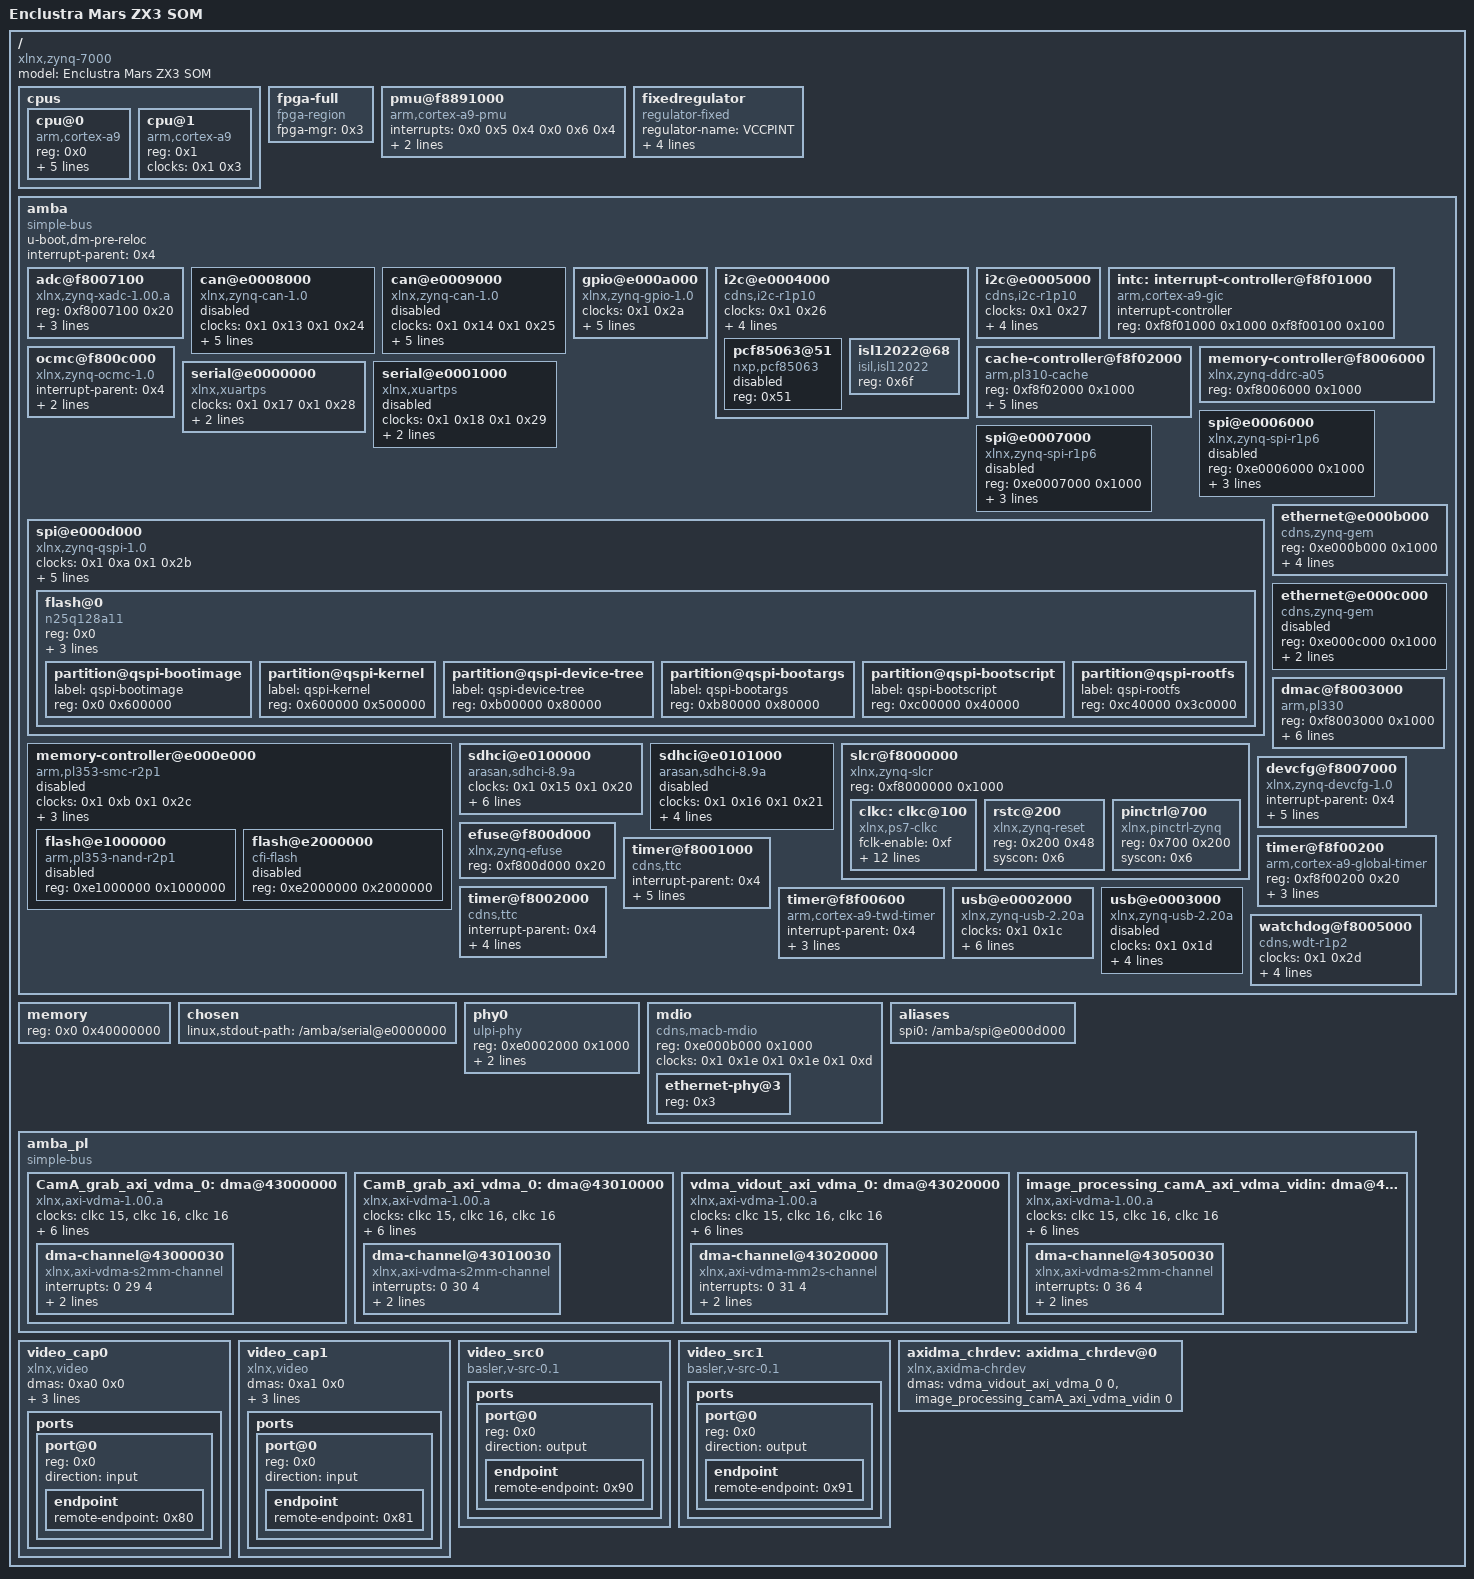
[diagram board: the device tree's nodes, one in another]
/dts-v1/;

/ {
	#address-cells = <0x1>;
	#size-cells = <0x1>;
	compatible = "xlnx,zynq-7000";
	model = "Enclustra Mars ZX3 SOM";

	cpus {
		#address-cells = <0x1>;
		#size-cells = <0x0>;

		cpu@0 {
			compatible = "arm,cortex-a9";
			device_type = "cpu";
			reg = <0x0>;
			clocks = <0x1 0x3>;
			clock-latency = <0x3e8>;
			cpu0-supply = <0x2>;
			operating-points = <0xbb2cb 0xf4240 0x5d966 0xf4240>;
		};

		cpu@1 {
			compatible = "arm,cortex-a9";
			device_type = "cpu";
			reg = <0x1>;
			clocks = <0x1 0x3>;
		};
	};

	fpga-full {
		compatible = "fpga-region";
		fpga-mgr = <0x3>;
		#address-cells = <0x1>;
		#size-cells = <0x1>;
		ranges;
	};

	pmu@f8891000 {
		compatible = "arm,cortex-a9-pmu";
		interrupts = <0x0 0x5 0x4 0x0 0x6 0x4>;
		interrupt-parent = <0x4>;
		reg = <0xf8891000 0x1000 0xf8893000 0x1000>;
	};

	fixedregulator {
		compatible = "regulator-fixed";
		regulator-name = "VCCPINT";
		regulator-min-microvolt = <0xf4240>;
		regulator-max-microvolt = <0xf4240>;
		regulator-boot-on;
		regulator-always-on;
		linux,phandle = <0x2>;
		phandle = <0x2>;
	};

	amba {
		u-boot,dm-pre-reloc;
		compatible = "simple-bus";
		#address-cells = <0x1>;
		#size-cells = <0x1>;
		interrupt-parent = <0x4>;
		ranges;

		adc@f8007100 {
			compatible = "xlnx,zynq-xadc-1.00.a";
			reg = <0xf8007100 0x20>;
			interrupts = <0x0 0x7 0x4>;
			interrupt-parent = <0x4>;
			clocks = <0x1 0xc>;
		};

		can@e0008000 {
			compatible = "xlnx,zynq-can-1.0";
			status = "disabled";
			clocks = <0x1 0x13 0x1 0x24>;
			clock-names = "can_clk", "pclk";
			reg = <0xe0008000 0x1000>;
			interrupts = <0x0 0x1c 0x4>;
			interrupt-parent = <0x4>;
			tx-fifo-depth = <0x40>;
			rx-fifo-depth = <0x40>;
		};

		can@e0009000 {
			compatible = "xlnx,zynq-can-1.0";
			status = "disabled";
			clocks = <0x1 0x14 0x1 0x25>;
			clock-names = "can_clk", "pclk";
			reg = <0xe0009000 0x1000>;
			interrupts = <0x0 0x33 0x4>;
			interrupt-parent = <0x4>;
			tx-fifo-depth = <0x40>;
			rx-fifo-depth = <0x40>;
		};

		gpio@e000a000 {
			compatible = "xlnx,zynq-gpio-1.0";
			#gpio-cells = <0x2>;
			clocks = <0x1 0x2a>;
			gpio-controller;
			interrupt-controller;
			#interrupt-cells = <0x2>;
			interrupt-parent = <0x4>;
			interrupts = <0x0 0x14 0x4>;
			reg = <0xe000a000 0x1000>;
		};

		i2c@e0004000 {
			compatible = "cdns,i2c-r1p10";
			status = "okay";
			clocks = <0x1 0x26>;
			interrupt-parent = <0x4>;
			interrupts = <0x0 0x19 0x4>;
			reg = <0xe0004000 0x1000>;
			#address-cells = <0x1>;
			#size-cells = <0x0>;
			clock-frequency = <100000>;
			
			pcf85063@51 {
				status = "disabled";
				compatible = "nxp,pcf85063";
				reg = <0x51>;
			};

			isl12022@68 {
				status = "okay";
				compatible = "isil,isl12022";
				reg = <0x6f>;
			};			
		};

		i2c@e0005000 {
			compatible = "cdns,i2c-r1p10";
			status = "okay";
			clocks = <0x1 0x27>;
			interrupt-parent = <0x4>;
			interrupts = <0x0 0x30 0x4>;
			reg = <0xe0005000 0x1000>;
			#address-cells = <0x1>;
			#size-cells = <0x0>;
			clock-frequency = <100000>;
		};

		intc:interrupt-controller@f8f01000 {
			compatible = "arm,cortex-a9-gic";
			#interrupt-cells = <0x3>;
			interrupt-controller;
			reg = <0xf8f01000 0x1000 0xf8f00100 0x100>;
			linux,phandle = <0x4>;
			phandle = <0x4>;
		};

		cache-controller@f8f02000 {
			compatible = "arm,pl310-cache";
			reg = <0xf8f02000 0x1000>;
			interrupts = <0x0 0x2 0x4>;
			arm,data-latency = <0x3 0x2 0x2>;
			arm,tag-latency = <0x2 0x2 0x2>;
			cache-unified;
			cache-level = <0x2>;
		};

		memory-controller@f8006000 {
			compatible = "xlnx,zynq-ddrc-a05";
			reg = <0xf8006000 0x1000>;
		};

		ocmc@f800c000 {
			compatible = "xlnx,zynq-ocmc-1.0";
			interrupt-parent = <0x4>;
			interrupts = <0x0 0x3 0x4>;
			reg = <0xf800c000 0x1000>;
		};

		serial@e0000000 {
			compatible = "xlnx,xuartps", "cdns,uart-r1p8";
			status = "okay";
			clocks = <0x1 0x17 0x1 0x28>;
			clock-names = "uart_clk", "pclk";
			reg = <0xe0000000 0x1000>;
			interrupts = <0x0 0x1b 0x4>;
		};

		serial@e0001000 {
			compatible = "xlnx,xuartps", "cdns,uart-r1p8";
			status = "disabled";
			clocks = <0x1 0x18 0x1 0x29>;
			clock-names = "uart_clk", "pclk";
			reg = <0xe0001000 0x1000>;
			interrupts = <0x0 0x32 0x4>;
		};

		spi@e0006000 {
			compatible = "xlnx,zynq-spi-r1p6";
			reg = <0xe0006000 0x1000>;
			status = "disabled";
			interrupt-parent = <0x4>;
			interrupts = <0x0 0x1a 0x4>;
			clocks = <0x1 0x19 0x1 0x22>;
			clock-names = "ref_clk", "pclk";
			#address-cells = <0x1>;
			#size-cells = <0x0>;
		};

		spi@e0007000 {
			compatible = "xlnx,zynq-spi-r1p6";
			reg = <0xe0007000 0x1000>;
			status = "disabled";
			interrupt-parent = <0x4>;
			interrupts = <0x0 0x31 0x4>;
			clocks = <0x1 0x1a 0x1 0x23>;
			clock-names = "ref_clk", "pclk";
			#address-cells = <0x1>;
			#size-cells = <0x0>;
		};

		spi@e000d000 {
			clock-names = "ref_clk", "pclk";
			clocks = <0x1 0xa 0x1 0x2b>;
			compatible = "xlnx,zynq-qspi-1.0";
			status = "okay";
			interrupt-parent = <0x4>;
			interrupts = <0x0 0x13 0x4>;
			reg = <0xe000d000 0x1000>;
			#address-cells = <0x1>;
			#size-cells = <0x0>;
			is-dual = <0x0>;
			num-cs = <0x1>;

			flash@0 {
				compatible = "n25q128a11";
				reg = <0x0>;
				spi-tx-bus-width = <0x1>;
				spi-rx-bus-width = <0x4>;
				spi-max-frequency = <0x2faf080>;
				#address-cells = <0x1>;
				#size-cells = <0x1>;

				partition@qspi-bootimage {
					label = "qspi-bootimage";
					reg = <0x0 0x600000>;
				};

				partition@qspi-kernel {
					label = "qspi-kernel";
					reg = <0x600000 0x500000>;
				};

				partition@qspi-device-tree {
					label = "qspi-device-tree";
					reg = <0xb00000 0x80000>;
				};

				partition@qspi-bootargs {
					label = "qspi-bootargs";
					reg = <0xb80000 0x80000>;
				};

				partition@qspi-bootscript {
					label = "qspi-bootscript";
					reg = <0xc00000 0x40000>;
				};

				partition@qspi-rootfs {
					label = "qspi-rootfs";
					reg = <0xc40000 0x3c0000>;
				};
			};
		};

		memory-controller@e000e000 {
			#address-cells = <0x1>;
			#size-cells = <0x1>;
			status = "disabled";
			clock-names = "memclk", "aclk";
			clocks = <0x1 0xb 0x1 0x2c>;
			compatible = "arm,pl353-smc-r2p1";
			interrupt-parent = <0x4>;
			interrupts = <0x0 0x12 0x4>;
			ranges;
			reg = <0xe000e000 0x1000>;

			flash@e1000000 {
				status = "disabled";
				compatible = "arm,pl353-nand-r2p1";
				reg = <0xe1000000 0x1000000>;
				#address-cells = <0x1>;
				#size-cells = <0x1>;
			};

			flash@e2000000 {
				status = "disabled";
				compatible = "cfi-flash";
				reg = <0xe2000000 0x2000000>;
				#address-cells = <0x1>;
				#size-cells = <0x1>;
			};
		};

		ethernet@e000b000 {
			compatible = "cdns,zynq-gem", "cdns,gem";
			reg = <0xe000b000 0x1000>;
			status = "okay";
			interrupts = <0x0 0x16 0x4>;
			clocks = <0x1 0x1e 0x1 0x1e 0x1 0xd>;
			clock-names = "pclk", "hclk", "tx_clk";
			#address-cells = <0x1>;
			#size-cells = <0x0>;
			phy-mode = "rgmii-id";
			phy-handle = <0x5>;
		};

		ethernet@e000c000 {
			compatible = "cdns,zynq-gem", "cdns,gem";
			reg = <0xe000c000 0x1000>;
			status = "disabled";
			interrupts = <0x0 0x2d 0x4>;
			clocks = <0x1 0x1f 0x1 0x1f 0x1 0xe>;
			clock-names = "pclk", "hclk", "tx_clk";
			#address-cells = <0x1>;
			#size-cells = <0x0>;
		};

		sdhci@e0100000 {
			compatible = "arasan,sdhci-8.9a";
			status = "okay";
			clock-names = "clk_xin", "clk_ahb";
			clocks = <0x1 0x15 0x1 0x20>;
			interrupt-parent = <0x4>;
			interrupts = <0x0 0x18 0x4>;
			reg = <0xe0100000 0x1000>;
			broken-adma2;
			broken-cd = <0x1>;
			wp-inverted = <0x1>;
		};

		sdhci@e0101000 {
			compatible = "arasan,sdhci-8.9a";
			status = "disabled";
			clock-names = "clk_xin", "clk_ahb";
			clocks = <0x1 0x16 0x1 0x21>;
			interrupt-parent = <0x4>;
			interrupts = <0x0 0x2f 0x4>;
			reg = <0xe0101000 0x1000>;
			broken-adma2;
		};

		slcr@f8000000 {
			#address-cells = <0x1>;
			#size-cells = <0x1>;
			compatible = "xlnx,zynq-slcr", "syscon", "simple-mfd";
			reg = <0xf8000000 0x1000>;
			ranges;
			linux,phandle = <0x6>;
			phandle = <0x6>;

			clkc:clkc@100 {
				#clock-cells = <0x1>;
				compatible = "xlnx,ps7-clkc";
				fclk-enable = <0xf>;
				clock-output-names = "armpll", "ddrpll", "iopll", "cpu_6or4x", "cpu_3or2x", "cpu_2x", "cpu_1x", "ddr2x", "ddr3x", "dci", "lqspi", "smc", "pcap", "gem0", "gem1", "fclk0", "fclk1", "fclk2", "fclk3", "can0", "can1", "sdio0", "sdio1", "uart0", "uart1", "spi0", "spi1", "dma", "usb0_aper", "usb1_aper", "gem0_aper", "gem1_aper", "sdio0_aper", "sdio1_aper", "spi0_aper", "spi1_aper", "can0_aper", "can1_aper", "i2c0_aper", "i2c1_aper", "uart0_aper", "uart1_aper", "gpio_aper", "lqspi_aper", "smc_aper", "swdt", "dbg_trc", "dbg_apb";
				reg = <0x100 0x100>;
				linux,phandle = <0x1>;
				phandle = <0x1>;
			};

			rstc@200 {
				compatible = "xlnx,zynq-reset";
				reg = <0x200 0x48>;
				#reset-cells = <0x1>;
				syscon = <0x6>;
			};

			pinctrl@700 {
				compatible = "xlnx,pinctrl-zynq";
				reg = <0x700 0x200>;
				syscon = <0x6>;
			};
		};

		dmac@f8003000 {
			compatible = "arm,pl330", "arm,primecell";
			reg = <0xf8003000 0x1000>;
			interrupt-parent = <0x4>;
			interrupt-names = "abort", "dma0", "dma1", "dma2", "dma3", "dma4", "dma5", "dma6", "dma7";
			interrupts = <0x0 0xd 0x4 0x0 0xe 0x4 0x0 0xf 0x4 0x0 0x10 0x4 0x0 0x11 0x4 0x0 0x28 0x4 0x0 0x29 0x4 0x0 0x2a 0x4 0x0 0x2b 0x4>;
			#dma-cells = <0x1>;
			#dma-channels = <0x8>;
			#dma-requests = <0x4>;
			clocks = <0x1 0x1b>;
			clock-names = "apb_pclk";
		};

		devcfg@f8007000 {
			compatible = "xlnx,zynq-devcfg-1.0";
			interrupt-parent = <0x4>;
			interrupts = <0x0 0x8 0x4>;
			reg = <0xf8007000 0x100>;
			clocks = <0x1 0xc 0x1 0xf 0x1 0x10 0x1 0x11 0x1 0x12>;
			clock-names = "ref_clk", "fclk0", "fclk1", "fclk2", "fclk3";
			syscon = <0x6>;
			linux,phandle = <0x3>;
			phandle = <0x3>;
		};

		efuse@f800d000 {
			compatible = "xlnx,zynq-efuse";
			reg = <0xf800d000 0x20>;
		};

		timer@f8f00200 {
			compatible = "arm,cortex-a9-global-timer";
			reg = <0xf8f00200 0x20>;
			interrupts = <0x1 0xb 0x301>;
			interrupt-parent = <0x4>;
			clocks = <0x1 0x4>;
		};

		timer@f8001000 {
			interrupt-parent = <0x4>;
			interrupts = <0x0 0xa 0x4 0x0 0xb 0x4 0x0 0xc 0x4>;
			compatible = "cdns,ttc";
			clocks = <0x1 0x6>;
			reg = <0xf8001000 0x1000>;
			/* added for BCON support */
			basler,trggen = <0x0>;
			/* added for BCON support end */
		};

		timer@f8002000 {
			interrupt-parent = <0x4>;
			interrupts = <0x0 0x25 0x4 0x0 0x26 0x4 0x0 0x27 0x4>;
			compatible = "cdns,ttc";
			clocks = <0x1 0x6>;
			reg = <0xf8002000 0x1000>;
		};

		timer@f8f00600 {
			interrupt-parent = <0x4>;
			interrupts = <0x1 0xd 0x301>;
			compatible = "arm,cortex-a9-twd-timer";
			reg = <0xf8f00600 0x20>;
			clocks = <0x1 0x4>;
		};

		usb@e0002000 {
			compatible = "xlnx,zynq-usb-2.20a", "chipidea,usb2";
			status = "okay";
			clocks = <0x1 0x1c>;
			interrupt-parent = <0x4>;
			interrupts = <0x0 0x15 0x4>;
			reg = <0xe0002000 0x1000>;
			phy_type = "ulpi";
			dr_mode = "host";
			usb-phy = <0x7>;
		};

		usb@e0003000 {
			compatible = "xlnx,zynq-usb-2.20a", "chipidea,usb2";
			status = "disabled";
			clocks = <0x1 0x1d>;
			interrupt-parent = <0x4>;
			interrupts = <0x0 0x2c 0x4>;
			reg = <0xe0003000 0x1000>;
			phy_type = "ulpi";
		};

		watchdog@f8005000 {
			clocks = <0x1 0x2d>;
			compatible = "cdns,wdt-r1p2";
			interrupt-parent = <0x4>;
			interrupts = <0x0 0x9 0x1>;
			reg = <0xf8005000 0x1000>;
			timeout-sec = <0xa>;
		};
	};

	memory {
		device_type = "memory";
		reg = <0x0 0x40000000>;
	};

	chosen {
		linux,stdout-path = "/amba/serial@e0000000";
	};

	phy0 {
		compatible = "ulpi-phy";
		#phy-cells = <0x0>;
		reg = <0xe0002000 0x1000>;
		view-port = <0x170>;
		drv-vbus;
		linux,phandle = <0x7>;
		phandle = <0x7>;
	};

	mdio {
		compatible = "cdns,macb-mdio";
		reg = <0xe000b000 0x1000>;
		clocks = <0x1 0x1e 0x1 0x1e 0x1 0xd>;
		clock-names = "pclk", "hclk", "tx_clk";
		#address-cells = <0x1>;
		#size-cells = <0x0>;

		ethernet-phy@3 {
			reg = <0x3>;
			linux,phandle = <0x5>;
			phandle = <0x5>;
		};
	};

	aliases {
		spi0 = "/amba/spi@e000d000";
	};

	/* pl added for BCON and  bperez77 xilinx_axidma support */
	amba_pl {
		#address-cells = <0x1>;
		#size-cells = <0x1>;
		compatible = "simple-bus";
		ranges;

		CamA_grab_axi_vdma_0: dma@43000000 {
			#dma-cells = <1>;
			clock-names = "s_axi_lite_aclk", "m_axi_s2mm_aclk", "m_axi_s2mm_aclk";
			clocks = <&clkc 15>, <&clkc 16>, <&clkc 16>;
			compatible = "xlnx,axi-vdma-1.00.a";
			interrupt-names = "s2mm_introut";
			interrupt-parent = <&intc>;
			interrupts = <0 29 4>;
			reg = <0x43000000 0x10000>;
			xlnx,addrwidth = <0x20>;
			xlnx,flush-fsync = <0x1>;
			xlnx,num-fstores = <0x1>;
			linux,phandle = <0xa0>;
			phandle = <0xa0>;

			dma-channel@43000030 {
				compatible = "xlnx,axi-vdma-s2mm-channel";
				interrupts = <0 29 4>;
				xlnx,datawidth = <0x20>;
				xlnx,device-id = <0x3>;
			};
		};

		CamB_grab_axi_vdma_0: dma@43010000 {
			#dma-cells = <1>;
			clock-names = "s_axi_lite_aclk", "m_axi_s2mm_aclk", "m_axi_s2mm_aclk";
			clocks = <&clkc 15>, <&clkc 16>, <&clkc 16>;
			compatible = "xlnx,axi-vdma-1.00.a";
			interrupt-names = "s2mm_introut";
			interrupt-parent = <&intc>;
			interrupts = <0 30 4>;
			reg = <0x43010000 0x10000>;
			xlnx,addrwidth = <0x20>;
			xlnx,flush-fsync = <0x1>;
			xlnx,num-fstores = <0x1>;
			linux,phandle = <0xa1>;
			phandle = <0xa1>;

			dma-channel@43010030 {
				compatible = "xlnx,axi-vdma-s2mm-channel";
				interrupts = <0 30 4>;
				xlnx,datawidth = <0x20>;
				xlnx,device-id = <0x4>;
			};
		};

		vdma_vidout_axi_vdma_0: dma@43020000 {
			#dma-cells = <1>;
			clock-names = "s_axi_lite_aclk", "m_axi_mm2s_aclk", "m_axi_mm2s_aclk";
			clocks = <&clkc 15>, <&clkc 16>, <&clkc 16>;
			compatible = "xlnx,axi-vdma-1.00.a";
			interrupt-names = "mm2s_introut";
			interrupt-parent = <&intc>;
			interrupts = <0 31 4>;
			reg = <0x43020000 0x10000>;
			xlnx,addrwidth = <0x20>;
			xlnx,flush-fsync = <0x1>;
			xlnx,num-fstores = <0x1>;

			dma-channel@43020000 {
				compatible = "xlnx,axi-vdma-mm2s-channel";
				interrupts = <0 31 4>;
				xlnx,datawidth = <0x18>;
				xlnx,device-id = <0x0>;
			};
		};

		image_processing_camA_axi_vdma_vidin: dma@43050000 {
			#dma-cells = <1>;
			clock-names = "s_axi_lite_aclk", "m_axi_s2mm_aclk", "m_axi_s2mm_aclk";
			clocks = <&clkc 15>, <&clkc 16>, <&clkc 16>;
			compatible = "xlnx,axi-vdma-1.00.a";
			interrupt-names = "s2mm_introut";
			interrupt-parent = <&intc>;
			interrupts = <0 36 4>;
			reg = <0x43050000 0x10000>;
			xlnx,addrwidth = <0x20>;
			xlnx,flush-fsync = <0x1>;
			xlnx,num-fstores = <0x1>;

			dma-channel@43050030 {
				compatible = "xlnx,axi-vdma-s2mm-channel";
				interrupts = <0 36 4>;
				xlnx,datawidth = <0x20>;
				xlnx,device-id = <0x1>;
			};
		};
	};
	/* pl added for BCON and  bperez77 xilinx_axidma support end */

	/* added for BCON support */
	video_cap0 {
		compatible = "xlnx,video";
		dmas = <0xa0 0x0>;
		dma-names = "port0";
		xlnx,video-format = <0xc>;
		xlnx,video-width = <0x8>;
		xlnx,cfa-pattern = "mono";
		
		ports {
			#address-cells = <0x1>;
			#size-cells = <0x0>;

			port@0 {
				reg = <0x0>;
				direction = "input";

				endpoint {
					remote-endpoint = <0x80>;
					linux,phandle = <0x90>;
					phandle = <0x90>;
				};
			};
		};
	};

	video_cap1 {
		compatible = "xlnx,video";
		dmas = <0xa1 0x0>;
		dma-names = "port0";
		xlnx,video-format = <0xc>;
		xlnx,video-width = <0x8>;
		xlnx,cfa-pattern = "mono";

		ports {
			#address-cells = <0x1>;
			#size-cells = <0x0>;

			port@0 {
				reg = <0x0>;
				direction = "input";

				endpoint {
					remote-endpoint = <0x81>;
					linux,phandle = <0x91>;
					phandle = <0x91>;
				};
			};
		};
	};

	video_src0 {
		compatible = "basler,v-src-0.1";

		ports {
			#address-cells = <0x1>;
			#size-cells = <0x0>;

			port@0 {
				reg = <0x0>;
				direction = "output";

				endpoint {
					remote-endpoint = <0x90>;
					linux,phandle = <0x80>;
					phandle = <0x80>;
				};
			};
		};
	};

	video_src1 {
		compatible = "basler,v-src-0.1";

		ports {
			#address-cells = <0x1>;
			#size-cells = <0x0>;

			port@0 {
				reg = <0x0>;
				direction = "output";

				endpoint {
					remote-endpoint = <0x91>;
					linux,phandle = <0x81>;
					phandle = <0x81>;
				};
			};
		};
	};
	/* added for BCON support end */

	/* added for bperez77 xilinx_axidma support */
	axidma_chrdev: axidma_chrdev@0 {
		compatible = "xlnx,axidma-chrdev";
		dmas = <&vdma_vidout_axi_vdma_0 0>, <&image_processing_camA_axi_vdma_vidin 0>;
		dma-names = "hdmi_tx_channel", "camA_rx_channel";
	};
	/* added for bperez77 xilinx_axidma support end */
};
